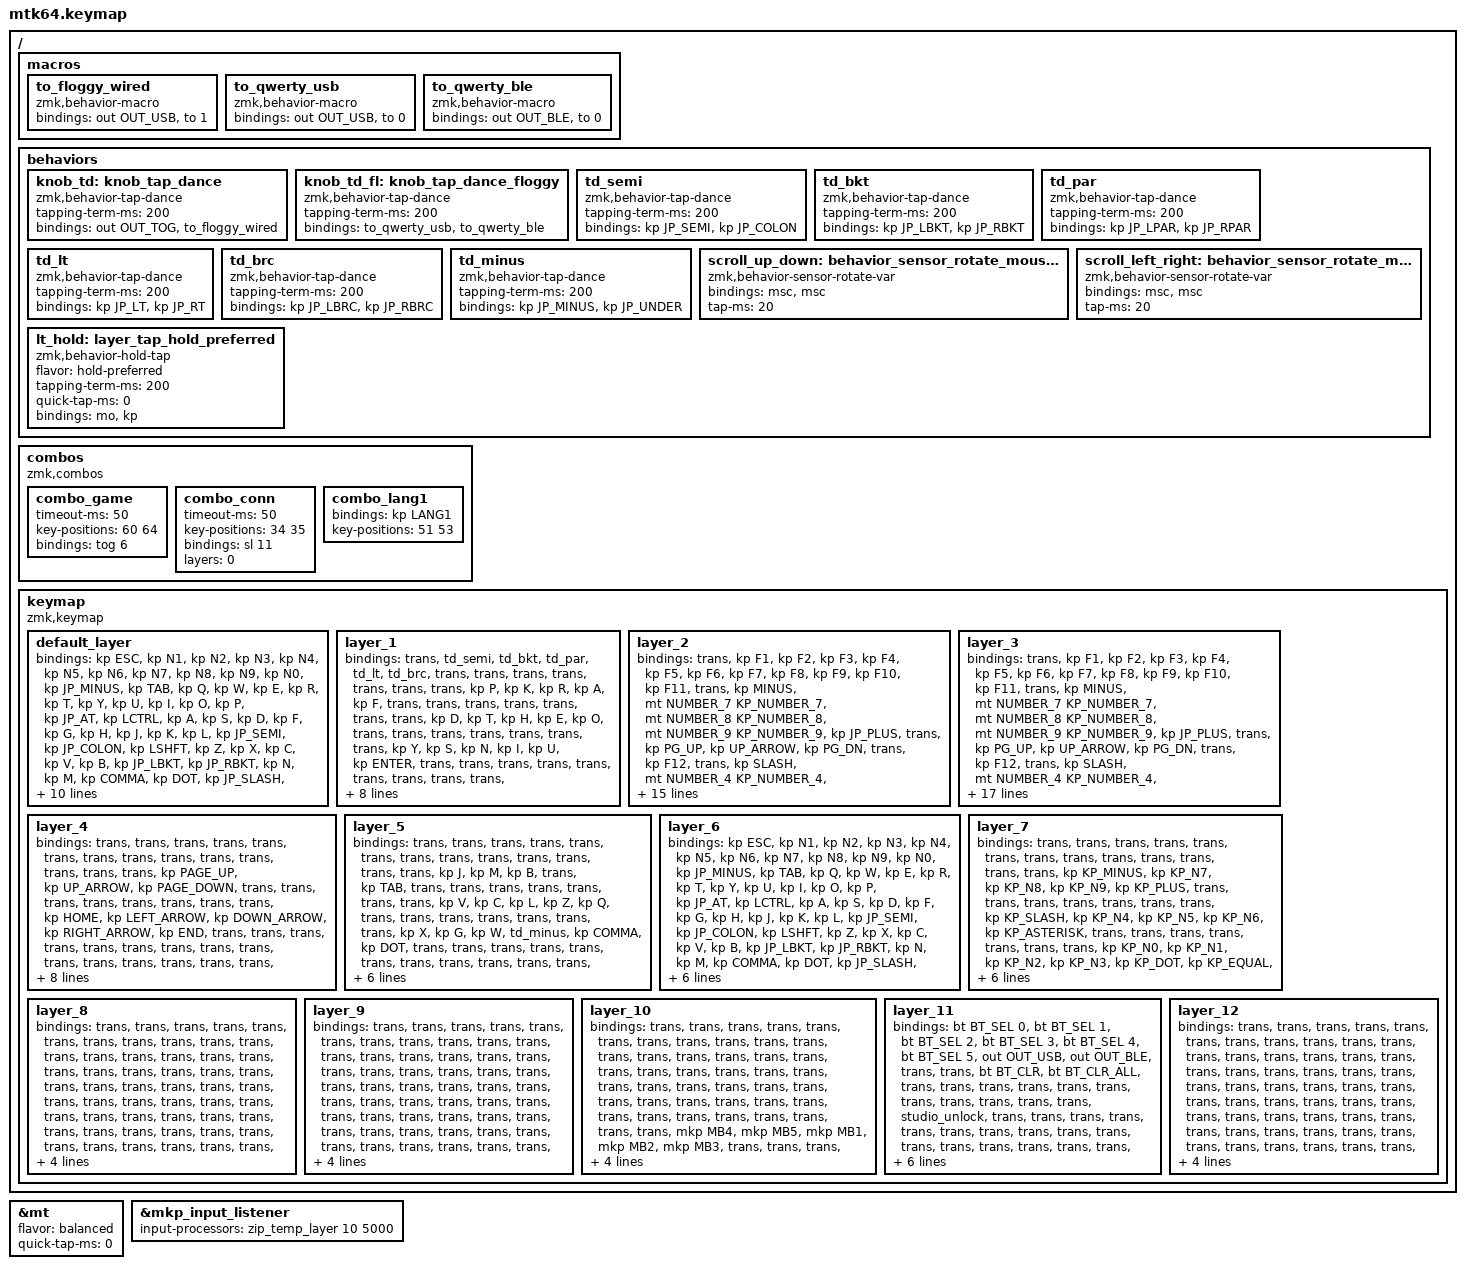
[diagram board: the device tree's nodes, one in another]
#include <input/processors.dtsi>
#include <behaviors.dtsi>
#include <dt-bindings/zmk/bt.h>
#include <dt-bindings/zmk/keys.h>
#include <dt-bindings/zmk/outputs.h>
#include <dt-bindings/zmk/pointing.h>
#include "keycode_japanese.h"

#define ZMK_POINTING_DEFAULT_SCRL_VAL 100

&mt {
    flavor = "balanced";
    quick-tap-ms = <0>;
};

// オートマウス層を 6 → 10 に変更

&mkp_input_listener { input-processors = <&zip_temp_layer 10 5000>; };

/ {
    macros {
        // 要件1: qwerty(有線/無線どちらからでも) → 有線のfloggy

        to_floggy_wired: to_floggy_wired {
            compatible = "zmk,behavior-macro";
            #binding-cells = <0>;
            bindings = <&out OUT_USB &to 1>;
        };

        // 要件3: floggy → 有線のままqwerty

        to_qwerty_usb: to_qwerty_usb {
            compatible = "zmk,behavior-macro";
            #binding-cells = <0>;
            bindings = <&out OUT_USB &to 0>;
        };

        // 要件2: floggy → 無線のqwerty

        to_qwerty_ble: to_qwerty_ble {
            compatible = "zmk,behavior-macro";
            #binding-cells = <0>;
            bindings = <&out OUT_BLE &to 0>;
        };
    };

    behaviors {
        // qwertyのノブ: 1タップ=有線無線切替 / 2タップ=有線floggyへ

        knob_td: knob_tap_dance {
            compatible = "zmk,behavior-tap-dance";
            #binding-cells = <0>;
            tapping-term-ms = <200>;
            bindings = <&out OUT_TOG>, <&to_floggy_wired>;
        };

        // floggyのノブ: 1タップ=有線qwertyへ / 2タップ=無線qwertyへ

        knob_td_fl: knob_tap_dance_floggy {
            compatible = "zmk,behavior-tap-dance";
            #binding-cells = <0>;
            tapping-term-ms = <200>;
            bindings = <&to_qwerty_usb>, <&to_qwerty_ble>;
        };

        // 記号タップダンス: 1タップ=開き / 2タップ=閉じ

        td_semi: td_semi {
            compatible = "zmk,behavior-tap-dance";
            #binding-cells = <0>;
            tapping-term-ms = <200>;
            bindings = <&kp JP_SEMI>, <&kp JP_COLON>;
        };

        td_bkt: td_bkt {
            compatible = "zmk,behavior-tap-dance";
            #binding-cells = <0>;
            tapping-term-ms = <200>;
            bindings = <&kp JP_LBKT>, <&kp JP_RBKT>;
        };

        td_par: td_par {
            compatible = "zmk,behavior-tap-dance";
            #binding-cells = <0>;
            tapping-term-ms = <200>;
            bindings = <&kp JP_LPAR>, <&kp JP_RPAR>;
        };

        td_lt: td_lt {
            compatible = "zmk,behavior-tap-dance";
            #binding-cells = <0>;
            tapping-term-ms = <200>;
            bindings = <&kp JP_LT>, <&kp JP_RT>;
        };

        td_brc: td_brc {
            compatible = "zmk,behavior-tap-dance";
            #binding-cells = <0>;
            tapping-term-ms = <200>;
            bindings = <&kp JP_LBRC>, <&kp JP_RBRC>;
        };

        td_minus: td_minus {
            compatible = "zmk,behavior-tap-dance";
            #binding-cells = <0>;
            tapping-term-ms = <200>;
            bindings = <&kp JP_MINUS>, <&kp JP_UNDER>;
        };

        scroll_up_down: behavior_sensor_rotate_mouse_wheel_up_down {
            compatible = "zmk,behavior-sensor-rotate-var";
            #sensor-binding-cells = <2>;
            bindings = <&msc>, <&msc>;

            tap-ms = <20>;
        };

        scroll_left_right: behavior_sensor_rotate_mouse_wheel_left_right {
            compatible = "zmk,behavior-sensor-rotate-var";
            #sensor-binding-cells = <2>;
            bindings = <&msc>, <&msc>;

            tap-ms = <20>;
        };

        lt_hold: layer_tap_hold_preferred {
            compatible = "zmk,behavior-hold-tap";
            #binding-cells = <2>;
            flavor = "hold-preferred";
            tapping-term-ms = <200>;
            quick-tap-ms = <0>;
            bindings = <&mo>, <&kp>;
        };
    };
};

/ {
    combos {
        compatible = "zmk,combos";

        // default層/ゲーム層を Del(60)+左BS(64) 同時押しでトグル

        combo_game {
            timeout-ms = <50>;
            key-positions = <60 64>;
            bindings = <&tog 6>;
        };

        // どの層でも ;(34)+:(35) 同時押し → 接続層(11)をオン/オフ

        combo_conn {
            timeout-ms = <50>;
            key-positions = <34 35>;
            bindings = <&sl 11>;
            layers = <0>;
        };

        combo_lang1 {
            bindings = <&kp LANG1>;
            key-positions = <51 53>;
        };
    };
};

/ {
    keymap {
        compatible = "zmk,keymap";

        /* ===== POSITION RULER (default_layer 準拠)  ※58/59 = ホイール周り =====
    0:Esc   1:1     2:2     3:3     4:4     5:5             6:6     7:7     8:8     9:9    10:0    11:-
   12:Tab  13:Q    14:W    15:E    16:R    17:T            18:Y    19:U    20:I    21:O    22:P    23:@
   24:Ctl  25:A    26:S    27:D    28:F    29:G            30:H    31:J    32:K    33:L    34:;    35::
   36:Sft  37:Z    38:X    39:C    40:V    41:B    42:[   43:]   44:N    45:M    46:,    47:.    48:/    49:\
   50:Alt  51:GUI          52:Spc   53:Grv   54:BS   55:Ent         56:^    57:¥
                   58:knob 59:→fl       60:Del      61:Ent       62:Ent  63:TG3
                                 64:BS        65:BS
   66:MO2  67:MO3  68:MO4                                  69:MO2  70:MO3  71:MO4
                              72:MO2  73:MO3  74:MO4
   --- 特殊キー: 32=lt4(K) 53=lt2(Grv) 54=lt3(BS) 55=lt4(Ent) 58=knob_td 59=→floggy 60=lt4(Del) 61=lt2(Ent) 64=lt3(BS) ---
   ============================================================================= */

        default_layer {
            // [0] qwerty英字 (ベース)

            bindings = <
&kp ESC  &kp N1  &kp N2  &kp N3  &kp N4  &kp N5  &kp N6  &kp N7  &kp N8  &kp N9  &kp N0  &kp JP_MINUS  &kp TAB  &kp Q  &kp W  &kp E  &kp R  &kp T  &kp Y  &kp U  &kp I  &kp O  &kp P  &kp JP_AT  &kp LCTRL  &kp A  &kp S  &kp D  &kp F  &kp G  &kp H  &kp J  &kp K  &kp L  &kp JP_SEMI  &kp JP_COLON  &kp LSHFT  &kp Z  &kp X  &kp C  &kp V  &kp B  &kp JP_LBKT  &kp JP_RBKT  &kp N  &kp M  &kp COMMA  &kp DOT  &kp JP_SLASH  &kp JP_BSLH  &kp LEFT_ALT  &kp LEFT_GUI  &lt 3 BACKSPACE  &lt_hold 2 LANG2  &lt 3 BACKSPACE  &lt 4 ENTER  &kp JP_CARET  &lt 4 JP_YEN  &knob_td  &to_floggy_wired  &lt 4 DEL  &lt 2 ENTER  &kp ENTER  &tog 3  &kp SPACE  &kp BACKSPACE  &mo 2  &mo 3  &mo 4  &mo 2  &mo 3  &mo 4  &mo 2  &mo 3  &mo 4
            >;

            sensor-bindings =
                <&scroll_up_down SCRL_UP SCRL_DOWN>,
                <&scroll_left_right SCRL_LEFT SCRL_RIGHT>;
        };

        layer_1 {
            // [1] floggy英字 (ベース)

            bindings = <
&trans  &td_semi  &td_bkt  &td_par  &td_lt  &td_brc  &trans  &trans  &trans  &trans  &trans  &trans  &trans  &kp P  &kp K  &kp R  &kp A  &kp F  &trans  &trans  &trans  &trans  &trans  &trans  &trans  &kp D  &kp T  &kp H  &kp E  &kp O  &trans  &trans  &trans  &trans  &trans  &trans  &trans  &kp Y  &kp S  &kp N  &kp I  &kp U  &kp ENTER  &trans  &trans  &trans  &trans  &trans  &trans  &trans  &trans  &trans  &lt_hold 5 BACKSPACE  &trans  &trans  &trans  &trans  &trans  &to_qwerty_usb  &to_qwerty_ble  &lt 4 DELETE  &trans  &trans  &trans  &trans  &trans  &trans  &trans  &trans  &trans  &trans  &trans  &trans  &trans  &trans
            >;

            sensor-bindings =
                <&scroll_up_down SCRL_UP SCRL_DOWN>,
                <&scroll_left_right SCRL_LEFT SCRL_RIGHT>;
        };

        layer_2 {
            // [2] プロファイル/システム

            bindings = <
&trans  &kp F1  &kp F2  &kp F3  &kp F4  &kp F5  &kp F6  &kp F7  &kp F8  &kp F9  &kp F10  &kp F11  &trans  &kp MINUS  &mt NUMBER_7 KP_NUMBER_7  &mt NUMBER_8 KP_NUMBER_8  &mt NUMBER_9 KP_NUMBER_9  &kp JP_PLUS  &trans  &kp PG_UP  &kp UP_ARROW  &kp PG_DN  &trans  &kp F12  &trans  &kp SLASH  &mt NUMBER_4 KP_NUMBER_4  &mt NUMBER_5 KP_NUMBER_5  &mt NUMBER_6 KP_NUMBER_6  &kp JP_ASTRK  &kp HOME  &kp LEFT_ARROW  &kp DOWN_ARROW  &kp RIGHT_ARROW  &kp END  &trans  &trans  &mt NUMBER_0 KP_NUMBER_0  &mt N1 KP_NUMBER_1  &mt NUMBER_2 KP_NUMBER_2  &mt NUMBER_3 KP_NUMBER_3  &kp PERIOD  &kp JP_EQUAL  &mkp MB4  &mkp MB5  &mkp MB1  &mkp MB2  &mkp MB3  &trans  &trans  &trans  &trans  &trans  &trans  &trans  &trans  &trans  &trans  &trans  &trans  &trans  &trans  &trans  &trans  &trans  &trans  &trans  &trans  &trans  &trans  &trans  &trans  &trans  &trans  &trans
            >;

            sensor-bindings =
                <&inc_dec_kp RBKT NON_US_HASH>,
                <&inc_dec_kp COMMA DOT>;
        };

        layer_3 {
            // [3] テンキー/F

            bindings = <
&trans  &kp F1  &kp F2  &kp F3  &kp F4  &kp F5  &kp F6  &kp F7  &kp F8  &kp F9  &kp F10  &kp F11  &trans  &kp MINUS  &mt NUMBER_7 KP_NUMBER_7  &mt NUMBER_8 KP_NUMBER_8  &mt NUMBER_9 KP_NUMBER_9  &kp JP_PLUS  &trans  &kp PG_UP  &kp UP_ARROW  &kp PG_DN  &trans  &kp F12  &trans  &kp SLASH  &mt NUMBER_4 KP_NUMBER_4  &mt NUMBER_5 KP_NUMBER_5  &mt NUMBER_6 KP_NUMBER_6  &kp JP_ASTRK  &kp HOME  &kp LEFT_ARROW  &kp DOWN_ARROW  &kp RIGHT_ARROW  &kp END  &trans  &trans  &mt NUMBER_0 KP_NUMBER_0  &mt NUMBER_1 KP_NUMBER_1  &mt NUMBER_2 KP_NUMBER_2  &mt NUMBER_3 KP_NUMBER_3  &kp PERIOD  &kp JP_EQUAL  &mkp MB4  &mkp MB5  &mkp MB1  &mkp MB2  &mkp MB3  &trans  &trans  &trans  &trans  &trans  &trans  &trans  &trans  &trans  &kp PSCRN  &trans  &trans  &trans  &trans  &trans  &trans  &trans  &trans  &trans  &trans  &trans  &trans  &trans  &trans  &trans  &trans  &trans
            >;

            sensor-bindings =
                <&scroll_up_down SCRL_UP SCRL_DOWN>,
                <&scroll_left_right SCRL_LEFT SCRL_RIGHT>;
        };

        layer_4 {
            // [4] カーソル (58→75へ修正)

            bindings = <
&trans  &trans  &trans  &trans  &trans  &trans  &trans  &trans  &trans  &trans  &trans  &trans  &trans  &trans  &kp PAGE_UP  &kp UP_ARROW  &kp PAGE_DOWN  &trans  &trans  &trans  &trans  &trans  &trans  &trans  &trans  &kp HOME  &kp LEFT_ARROW  &kp DOWN_ARROW  &kp RIGHT_ARROW  &kp END  &trans  &trans  &trans  &trans  &trans  &trans  &trans  &trans  &trans  &trans  &trans  &trans  &trans  &trans  &trans  &trans  &trans  &trans  &trans  &trans  &trans  &trans  &trans  &trans  &trans  &trans  &trans  &trans  &trans  &trans  &trans  &trans  &trans  &trans  &trans  &trans  &trans  &trans  &trans  &trans  &trans  &trans  &trans  &trans  &trans
            >;

            sensor-bindings =
                <&scroll_up_down SCRL_UP SCRL_DOWN>,
                <&scroll_left_right SCRL_LEFT SCRL_RIGHT>;
        };

        layer_5 {
            // [5] floggy英字2

            bindings = <
&trans  &trans  &trans  &trans  &trans  &trans  &trans  &trans  &trans  &trans  &trans  &trans  &trans  &kp J  &kp M  &kp B  &trans  &kp TAB  &trans  &trans  &trans  &trans  &trans  &trans  &trans  &kp V  &kp C  &kp L  &kp Z  &kp Q  &trans  &trans  &trans  &trans  &trans  &trans  &trans  &kp X  &kp G  &kp W  &td_minus  &kp COMMA  &kp DOT  &trans  &trans  &trans  &trans  &trans  &trans  &trans  &trans  &trans  &trans  &trans  &trans  &trans  &trans  &trans  &trans  &trans  &trans  &trans  &trans  &trans  &trans  &trans  &trans  &trans  &trans  &trans  &trans  &trans  &trans  &trans  &trans
            >;

            sensor-bindings =
                <&inc_dec_kp UP DOWN_ARROW>,
                <&inc_dec_kp LEFT_ARROW RIGHT_ARROW>;
        };

        layer_6 {
            // [6] ゲーム (旧layer_11から移動)

            bindings = <
&kp ESC  &kp N1  &kp N2  &kp N3  &kp N4  &kp N5  &kp N6  &kp N7  &kp N8  &kp N9  &kp N0  &kp JP_MINUS  &kp TAB  &kp Q  &kp W  &kp E  &kp R  &kp T  &kp Y  &kp U  &kp I  &kp O  &kp P  &kp JP_AT  &kp LCTRL  &kp A  &kp S  &kp D  &kp F  &kp G  &kp H  &kp J  &kp K  &kp L  &kp JP_SEMI  &kp JP_COLON  &kp LSHFT  &kp Z  &kp X  &kp C  &kp V  &kp B  &kp JP_LBKT  &kp JP_RBKT  &kp N  &kp M  &kp COMMA  &kp DOT  &kp JP_SLASH  &kp JP_BSLH  &kp LEFT_ALT  &kp LCTRL  &kp SPACE  &kp GRAVE  &kp BACKSPACE  &kp RIGHT_SHIFT  &kp JP_CARET  &kp JP_YEN  &kp TAB  &mkp MCLK  &kp DEL  &kp ENTER  &kp ENTER  &tog 3  &kp BACKSPACE  &kp RCTRL  &mo 2  &mo 3  &mo 4  &mo 2  &mo 3  &mo 4  &mo 2  &mo 3  &mo 4
            >;
        };

        layer_7 {
            // [7] テンキー予備 (旧layer_7)

            bindings = <
&trans  &trans  &trans  &trans  &trans  &trans  &trans  &trans  &trans  &trans  &trans  &trans  &trans  &kp KP_MINUS  &kp KP_N7  &kp KP_N8  &kp KP_N9  &kp KP_PLUS  &trans  &trans  &trans  &trans  &trans  &trans  &trans  &kp KP_SLASH  &kp KP_N4  &kp KP_N5  &kp KP_N6  &kp KP_ASTERISK  &trans  &trans  &trans  &trans  &trans  &trans  &trans  &kp KP_N0  &kp KP_N1  &kp KP_N2  &kp KP_N3  &kp KP_DOT  &kp KP_EQUAL  &trans  &trans  &trans  &trans  &trans  &trans  &trans  &trans  &trans  &trans  &trans  &trans  &trans  &trans  &trans  &trans  &trans  &trans  &trans  &trans  &trans  &trans  &trans  &trans  &trans  &trans  &trans  &trans  &trans  &trans  &trans  &trans
            >;
        };

        layer_8 {
            // [8] 予約 (空)

            bindings = <
&trans  &trans  &trans  &trans  &trans  &trans  &trans  &trans  &trans  &trans  &trans  &trans  &trans  &trans  &trans  &trans  &trans  &trans  &trans  &trans  &trans  &trans  &trans  &trans  &trans  &trans  &trans  &trans  &trans  &trans  &trans  &trans  &trans  &trans  &trans  &trans  &trans  &trans  &trans  &trans  &trans  &trans  &trans  &trans  &trans  &trans  &trans  &trans  &trans  &trans  &trans  &trans  &trans  &trans  &trans  &trans  &trans  &trans  &trans  &trans  &trans  &trans  &trans  &trans  &trans  &trans  &trans  &trans  &trans  &trans  &trans  &trans  &trans  &trans  &trans
            >;
        };

        layer_9 {
            // [9] 予約 (空)

            bindings = <
&trans  &trans  &trans  &trans  &trans  &trans  &trans  &trans  &trans  &trans  &trans  &trans  &trans  &trans  &trans  &trans  &trans  &trans  &trans  &trans  &trans  &trans  &trans  &trans  &trans  &trans  &trans  &trans  &trans  &trans  &trans  &trans  &trans  &trans  &trans  &trans  &trans  &trans  &trans  &trans  &trans  &trans  &trans  &trans  &trans  &trans  &trans  &trans  &trans  &trans  &trans  &trans  &trans  &trans  &trans  &trans  &trans  &trans  &trans  &trans  &trans  &trans  &trans  &trans  &trans  &trans  &trans  &trans  &trans  &trans  &trans  &trans  &trans  &trans  &trans
            >;
        };

        layer_10 {
            // [10] オートマウス (最上位)

            bindings = <
&trans  &trans  &trans  &trans  &trans  &trans  &trans  &trans  &trans  &trans  &trans  &trans  &trans  &trans  &trans  &trans  &trans  &trans  &trans  &trans  &trans  &trans  &trans  &trans  &trans  &trans  &trans  &trans  &trans  &trans  &trans  &trans  &trans  &trans  &trans  &trans  &trans  &trans  &trans  &trans  &trans  &trans  &trans  &mkp MB4  &mkp MB5  &mkp MB1  &mkp MB2  &mkp MB3  &trans  &trans  &trans  &trans  &trans  &trans  &trans  &trans  &trans  &trans  &trans  &trans  &trans  &trans  &trans  &trans  &trans  &trans  &trans  &trans  &trans  &trans  &trans  &trans  &trans  &trans  &trans
            >;
        };

        layer_11 {
            // [11] 接続 (旧layer_12から移動)

            bindings = <
&bt BT_SEL 0  &bt BT_SEL 1  &bt BT_SEL 2  &bt BT_SEL 3  &bt BT_SEL 4  &bt BT_SEL 5  &out OUT_USB  &out OUT_BLE  &trans  &trans  &bt BT_CLR  &bt BT_CLR_ALL  &trans  &trans  &trans  &trans  &trans  &trans  &trans  &trans  &trans  &trans  &trans  &studio_unlock  &trans  &trans  &trans  &trans  &trans  &trans  &trans  &trans  &trans  &trans  &trans  &trans  &trans  &trans  &trans  &trans  &trans  &trans  &trans  &trans  &trans  &trans  &trans  &trans  &trans  &trans  &trans  &trans  &trans  &trans  &trans  &trans  &trans  &trans  &trans  &trans  &trans  &trans  &trans  &trans  &trans  &trans  &trans  &trans  &trans  &trans  &trans  &trans  &trans  &trans  &trans
            >;
        };

        layer_12 {
            // [12] 予約 (空)

            bindings = <
&trans  &trans  &trans  &trans  &trans  &trans  &trans  &trans  &trans  &trans  &trans  &trans  &trans  &trans  &trans  &trans  &trans  &trans  &trans  &trans  &trans  &trans  &trans  &trans  &trans  &trans  &trans  &trans  &trans  &trans  &trans  &trans  &trans  &trans  &trans  &trans  &trans  &trans  &trans  &trans  &trans  &trans  &trans  &trans  &trans  &trans  &trans  &trans  &trans  &trans  &trans  &trans  &trans  &trans  &trans  &trans  &trans  &trans  &trans  &trans  &trans  &trans  &trans  &trans  &trans  &trans  &trans  &trans  &trans  &trans  &trans  &trans  &trans  &trans  &trans
            >;
        };
    };
};
